# f2838x_cm_scb_regs register map
Vendor: Texas Instruments
Peripheral module from a debugger description file (folder C2000).
Address unit: 16 bits
Registers are 32-bit, read-write, no defined reset value unless marked. A register's access mark holds for its fields unless they carry their own. Offsets are as the file gives them; lines under a group give offsets from that group; [hi:lo] are bit positions; {n}, {i} and the like mark numbered series; 'fields as' and 'values as' point back to an identical list; <NAME> marks a mode.

## SCB — SCB Registers
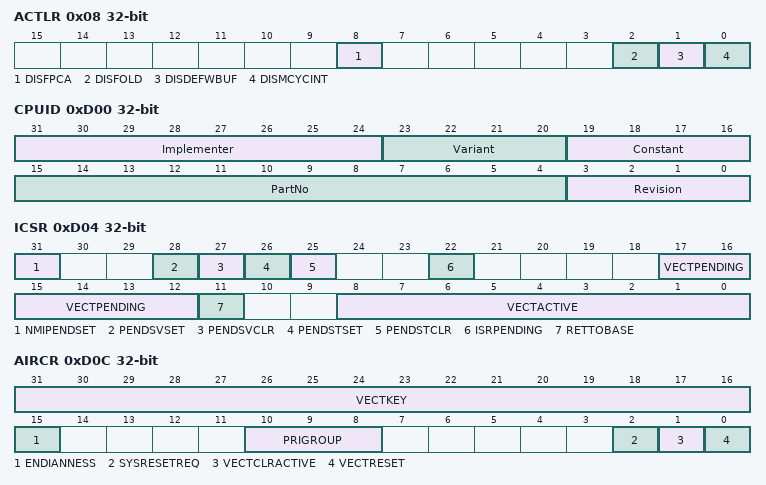
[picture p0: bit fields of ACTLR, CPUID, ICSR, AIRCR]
0x08 ACTLR — Auxiliary Control Register
  [8] DISFPCA — Disables automatic update of CONTROL.FPCA.
  [2] DISFOLD — Disables IT folding.
  [1] DISDEFWBUF — Disable write buffer on default memory map.
  [0] DISMCYCINT — Disable interruption of load/store multiple instruction.
0xD00 CPUID ro — CPUID Base Register
  [31:24] Implementer, [23:20] Variant, [19:16] Constant, [15:4] PartNo, [3:0] Revision
0xD04 ICSR access per field — Interrupt Control and State Register
  [31] NMIPENDSET rw — NMI set-pending bit.
  [28] PENDSVSET rw — PendSV set-pending bit.
  [27] PENDSVCLR rw — PendSV clear-pending bit.
  [26] PENDSTSET rw — SysTick exception set-pending bit.
  [25] PENDSTCLR rw — SysTick exception clear-pending bit
  [22] ISRPENDING ro — Interrupt pending flag
  [17:12] VECTPENDING ro — Exception number of highest priority pending exception.
  [11] RETTOBASE ro — Indicates presence of preempted active exceptions.
  [8:0] VECTACTIVE ro — Active exception number
0xD08 VTOR — Vector Table Offset Register
  [31:7] TBLOFF — Vector table offset.
0xD0C AIRCR access per field — Application Interrupt and Reset Control Register
  [31:16] VECTKEY rw — Vector Key.
  [15] ENDIANNESS ro — Data endianness bit
  [10:8] PRIGROUP rw — Interrupt priority grouping field
  [2] SYSRESETREQ rw — System reset request bit
  [1] VECTCLRACTIVE rw — Reserved for Debug use.
  [0] VECTRESET rw — CPU Reset
0xD10 SCR — System Control Register
  [1] SLEEPONEXIT — sleep-on-exit when returning from Handler mode.
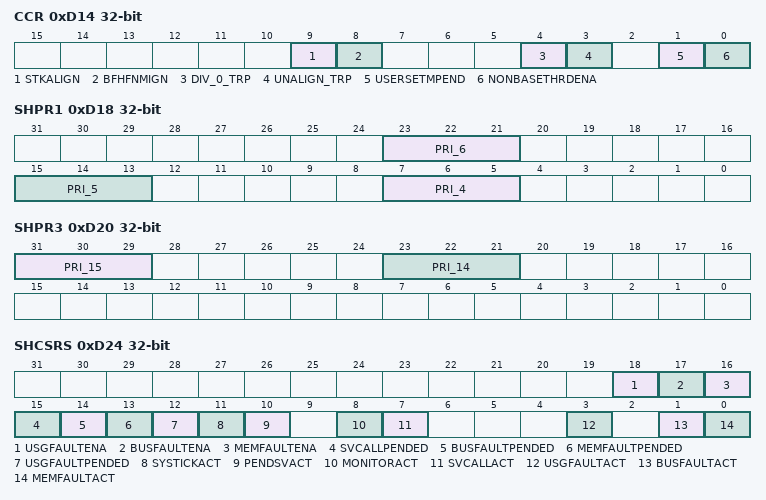
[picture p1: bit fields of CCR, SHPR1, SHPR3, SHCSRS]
0xD14 CCR — Configuration and Control Register
  [9] STKALIGN — Indicates stack alignment on exception entry.
  [8] BFHFNMIGN — Ignore data BusFaults caused by load and store instructions.
  [4] DIV_0_TRP — faulting/halting on DIV by 0 exception.
  [3] UNALIGN_TRP — Enables unaligned access traps.
  [1] USERSETMPEND — Enables unprivileged software access to the STIR.
  [0] NONBASETHRDENA — Indicates how the processor enters Thread mode
0xD18 SHPR1 — System Handler Priority Register 1
  [23:21] PRI_6 — Priority of system handler 6, UsageFault
  [15:13] PRI_5 — Priority of system handler 5, BusFault
  [7:5] PRI_4 — Priority of system handler 4, MemManage
0xD1C SHPR2 — System Handler Priority Register 2
  [31:29] PRI_11 — Priority of system handler 11, SVCall
0xD20 SHPR3 — System Handler Priority Register 3
  [31:29] PRI_15 — Priority of system handler 15, SysTick exception
  [23:21] PRI_14 — Priority of system handler 14, PendSV
0xD24 SHCSRS access per field — System Handler Control and State Register
  [18] USGFAULTENA rw — UsageFault enable bit
  [17] BUSFAULTENA rw — BusFault enable bit
  [16] MEMFAULTENA rw — MemManage enable bit
  [15] SVCALLPENDED rw — SVCall pending bit
  [14] BUSFAULTPENDED rw — BusFault exception pending bit
  [13] MEMFAULTPENDED rw — MemManage exception pending bit
  [12] USGFAULTPENDED rw — UsageFault exception pending bit
  [11] SYSTICKACT ro — SysTick exception active bit
  [10] PENDSVACT ro — PendSV exception active bit
  [8] MONITORACT ro — Debug monitor active bit
  [7] SVCALLACT ro — SVCall active bit
  [3] USGFAULTACT ro — UsageFault exception active bit
  [1] BUSFAULTACT ro — BusFault exception active bit
  [0] MEMFAULTACT ro — MemManage exception active bit
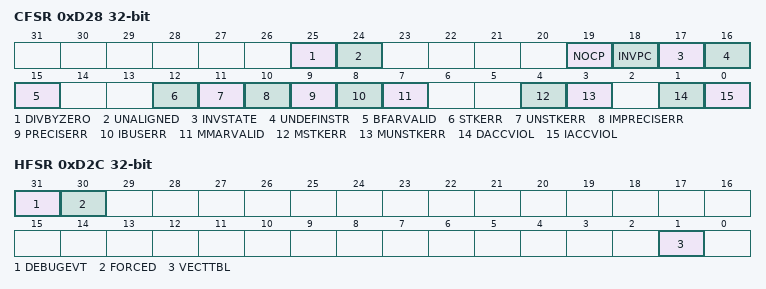
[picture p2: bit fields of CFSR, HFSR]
0xD28 CFSR — Configurable Fault Status Register
  [25] DIVBYZERO — Divide by zero UsageFault
  [24] UNALIGNED — Unaligned access UsageFault
  [19] NOCP — No coprocessor UsageFault
  [18] INVPC — Invalid PC load UsageFault
  [17] INVSTATE — Invalid state UsageFault
  [16] UNDEFINSTR — Undefined instruction UsageFault
  [15] BFARVALID — BusFault Address Register (BFAR) valid flag
  [12] STKERR — BusFault on stacking for exception entry
  [11] UNSTKERR — BusFault on unstacking for a return from exception
  [10] IMPRECISERR — Imprecise data bus error
  [9] PRECISERR — Precise data bus error
  [8] IBUSERR — Instruction bus error
  [7] MMARVALID — MemManage Fault Address Register (MMFAR) valid flag
  [4] MSTKERR — MemManage fault on stacking for exception entry
  [3] MUNSTKERR — MemManage fault on unstacking for a return from exception
  [1] DACCVIOL — Data access violation flag
  [0] IACCVIOL — Instruction access violation flag
0xD2C HFSR — HardFault Status Register
  [31] DEBUGEVT — Indicates a forced DEBUG event fault
  [30] FORCED — Indicates a forced hard fault
  [1] VECTTBL — BusFault on a vector table read.
0xD34 MMFAR — MemManage Fault Address Register
  [31:0] ADDRESS — Address of the location that generated the MemManage fault
0xD38 BFAR — BusFault Address Register
  [31:0] ADDRESS — Address of the location that generated the BusFault
0xD3C AFSR — Auxiliary Fault Status Register
  [31:0] ADDRESS — The bits map to the AUXFAULT input signals.
